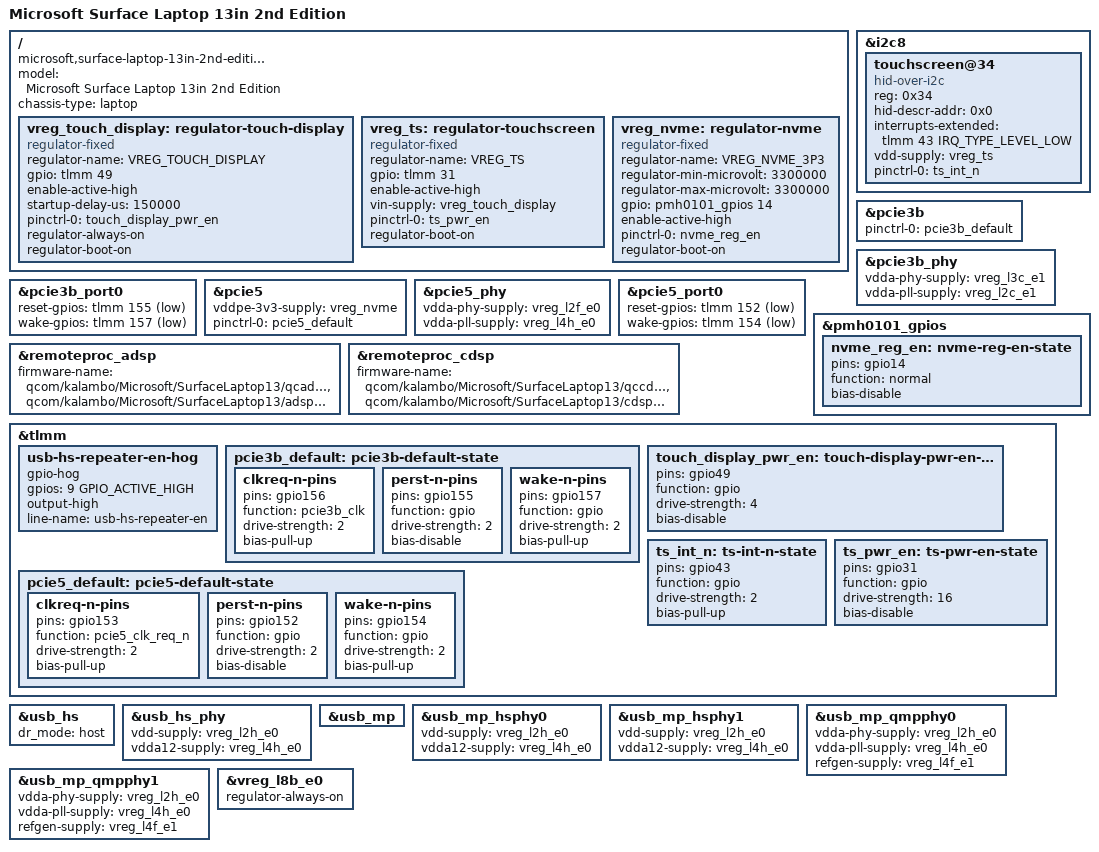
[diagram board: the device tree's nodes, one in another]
// SPDX-License-Identifier: BSD-3-Clause
/*
 * Microsoft Surface Laptop 13-inch (2nd Edition), model 2145, with the
 * 6-core Snapdragon X2 Plus X2P-42-100 (Kalambo).
 *
 * Written from the ACPI tables in Microsoft's firmware download
 * (Surface_UEFI_8.5175.155). Next to the parts kalambo-microsoft-surface.dtsi
 * shares with the Surface Pro 12-inch (2nd Edition), the laptop has a
 * touchscreen (MSHW0816) at 0x34 behind the switch the panel also depends
 * on, as on the Surface Laptop 8 15-inch. It has the USB 2.0 controller
 * (ACPI USB4 @ 0xa200000) with one internal port, and the multiport
 * controller (ACPI USB3) with the USB-A port; the ACPI tables have no I2C
 * keyboard or touchpad. Its drive is NVMe: the INA4230 power monitor
 * channel is STORAGE_SSD_3P3V.
 *
 * Copyright (c) Qualcomm Technologies, Inc. and/or its subsidiaries.
 */
/dts-v1/;

#include "kalambo.dtsi"
#include "kalambo-microsoft-surface.dtsi"

/ {
	model = "Microsoft Surface Laptop 13in 2nd Edition";
	compatible = "microsoft,surface-laptop-13in-2nd-edition", "qcom,kalambo";
	chassis-type = "laptop";

	/*
	 * ACPI power resource TDPR: TLMM 49, then 150 ms. Both the touchscreen
	 * (ITCH) and the panel (GPU0.MON0) depend on it, so it stays on.
	 */
	vreg_touch_display: regulator-touch-display {
		compatible = "regulator-fixed";

		regulator-name = "VREG_TOUCH_DISPLAY";

		gpio = <&tlmm 49 GPIO_ACTIVE_HIGH>;
		enable-active-high;
		startup-delay-us = <150000>;

		pinctrl-0 = <&touch_display_pwr_en>;
		pinctrl-names = "default";

		regulator-always-on;
		regulator-boot-on;
	};

	/* ACPI ITCH _PS0 drives TLMM 31 high and _PS3 drives it low. */
	vreg_ts: regulator-touchscreen {
		compatible = "regulator-fixed";

		regulator-name = "VREG_TS";

		gpio = <&tlmm 31 GPIO_ACTIVE_HIGH>;
		enable-active-high;

		vin-supply = <&vreg_touch_display>;

		pinctrl-0 = <&ts_pwr_en>;
		pinctrl-names = "default";

		regulator-boot-on;
	};

	vreg_nvme: regulator-nvme {
		compatible = "regulator-fixed";

		regulator-name = "VREG_NVME_3P3";
		regulator-min-microvolt = <3300000>;
		regulator-max-microvolt = <3300000>;

		gpio = <&pmh0101_gpios 14 GPIO_ACTIVE_HIGH>;
		enable-active-high;

		pinctrl-0 = <&nvme_reg_en>;
		pinctrl-names = "default";

		regulator-boot-on;
	};
};

&i2c8 {
	/*
	 * ACPI \_SB.I2C9.ITCH, MSHW0816: 0x34 at 400 kHz, HID descriptor
	 * register 0 (its _DSM function 1 returns 0), interrupt TLMM 43 level
	 * low with a pull-up.
	 */
	touchscreen@34 {
		compatible = "hid-over-i2c";
		reg = <0x34>;
		hid-descr-addr = <0x0>;
		interrupts-extended = <&tlmm 43 IRQ_TYPE_LEVEL_LOW>;
		vdd-supply = <&vreg_ts>;

		pinctrl-0 = <&ts_int_n>;
		pinctrl-names = "default";
	};
};

/*
 * ACPI PCI5 and PCI7 both declare an NVMe drive (NVME), and which port the
 * firmware enables (PRP5, PRP7) is filled in at boot. PCI5 is the Surface
 * Laptop 8's drive port; PCI7 (pcie3b, @ 0x74000000) is a port the Surface
 * Laptop 8 uses for an external card slot and this laptop's tables turn
 * into a plain NVMe port. Both are described; the one without a drive
 * fails link training.
 */
&pcie3b {
	pinctrl-0 = <&pcie3b_default>;
	pinctrl-names = "default";

	status = "okay";
};

/* ACPI PCI7 power table: L3C_E1 at 0.936 V and L2C_E1 at 1.2 V */
&pcie3b_phy {
	vdda-phy-supply = <&vreg_l3c_e1>;
	vdda-pll-supply = <&vreg_l2c_e1>;

	status = "okay";
};

/* ACPI PCI7: reset TLMM 155, wake TLMM 157 (virtual pin 0x240) */
&pcie3b_port0 {
	reset-gpios = <&tlmm 155 GPIO_ACTIVE_LOW>;
	wake-gpios = <&tlmm 157 GPIO_ACTIVE_LOW>;
};

&pcie5 {
	vddpe-3v3-supply = <&vreg_nvme>;

	pinctrl-0 = <&pcie5_default>;
	pinctrl-names = "default";

	status = "okay";
};

&pcie5_phy {
	vdda-phy-supply = <&vreg_l2f_e0>;
	vdda-pll-supply = <&vreg_l4h_e0>;

	status = "okay";
};

/* ACPI PCI5: reset TLMM 152, wake TLMM 154 (virtual pin 0x1c0) */
&pcie5_port0 {
	reset-gpios = <&tlmm 152 GPIO_ACTIVE_LOW>;
	wake-gpios = <&tlmm 154 GPIO_ACTIVE_LOW>;
};

&pmh0101_gpios {
	nvme_reg_en: nvme-reg-en-state {
		pins = "gpio14";
		function = "normal";
		bias-disable;
	};
};

&remoteproc_adsp {
	firmware-name = "qcom/kalambo/Microsoft/SurfaceLaptop13/qcadsp8480.mbn",
			"qcom/kalambo/Microsoft/SurfaceLaptop13/adsp_dtbs.elf";

	status = "okay";
};

&remoteproc_cdsp {
	firmware-name = "qcom/kalambo/Microsoft/SurfaceLaptop13/qccdsp8480.mbn",
			"qcom/kalambo/Microsoft/SurfaceLaptop13/cdsp_dtbs.elf";

	status = "okay";
};

&tlmm {
	/*
	 * ACPI USB4 (the USB 2.0 controller) drives TLMM 9 high in _PS0 and
	 * nothing low again: the enable of its eUSB2 repeater, which has no
	 * I2C address in the tables.
	 */
	usb-hs-repeater-en-hog {
		gpio-hog;
		gpios = <9 GPIO_ACTIVE_HIGH>;
		output-high;
		line-name = "usb-hs-repeater-en";
	};

	pcie3b_default: pcie3b-default-state {
		clkreq-n-pins {
			pins = "gpio156";
			function = "pcie3b_clk";
			drive-strength = <2>;
			bias-pull-up;
		};

		perst-n-pins {
			pins = "gpio155";
			function = "gpio";
			drive-strength = <2>;
			bias-disable;
		};

		wake-n-pins {
			pins = "gpio157";
			function = "gpio";
			drive-strength = <2>;
			bias-pull-up;
		};
	};

	pcie5_default: pcie5-default-state {
		clkreq-n-pins {
			pins = "gpio153";
			function = "pcie5_clk_req_n";
			drive-strength = <2>;
			bias-pull-up;
		};

		perst-n-pins {
			pins = "gpio152";
			function = "gpio";
			drive-strength = <2>;
			bias-disable;
		};

		wake-n-pins {
			pins = "gpio154";
			function = "gpio";
			drive-strength = <2>;
			bias-pull-up;
		};
	};

	touch_display_pwr_en: touch-display-pwr-en-state {
		pins = "gpio49";
		function = "gpio";
		drive-strength = <4>;
		bias-disable;
	};

	ts_int_n: ts-int-n-state {
		pins = "gpio43";
		function = "gpio";
		drive-strength = <2>;
		bias-pull-up;
	};

	ts_pwr_en: ts-pwr-en-state {
		pins = "gpio31";
		function = "gpio";
		drive-strength = <16>;
		bias-disable;
	};
};

/*
 * ACPI USB4 @ 0xa200000, the USB 2.0 controller, with one internal port
 * (_UPC not connectable by the user). Its PHY rails are those of its PEP
 * table: L2H_E0 and L4H_E0.
 */
&usb_hs {
	dr_mode = "host";

	status = "okay";
};

&usb_hs_phy {
	vdd-supply = <&vreg_l2h_e0>;
	vdda12-supply = <&vreg_l4h_e0>;

	status = "okay";
};

/*
 * Multiport controller (ACPI USB3): the USB-A port and an internal port.
 * _PS0 drives the enables of the two eUSB2 repeaters, TLMM 8 and 184, high,
 * and the tables give the repeaters no I2C address, so they are left as
 * the firmware set them, as on the Surface Laptop 8.
 */
&usb_mp {
	status = "okay";
};

&usb_mp_hsphy0 {
	vdd-supply = <&vreg_l2h_e0>;
	vdda12-supply = <&vreg_l4h_e0>;

	status = "okay";
};

&usb_mp_hsphy1 {
	vdd-supply = <&vreg_l2h_e0>;
	vdda12-supply = <&vreg_l4h_e0>;

	status = "okay";
};

&usb_mp_qmpphy0 {
	vdda-phy-supply = <&vreg_l2h_e0>;
	vdda-pll-supply = <&vreg_l4h_e0>;
	refgen-supply = <&vreg_l4f_e1>;

	status = "okay";
};

&usb_mp_qmpphy1 {
	vdda-phy-supply = <&vreg_l2h_e0>;
	vdda-pll-supply = <&vreg_l4h_e0>;
	refgen-supply = <&vreg_l4f_e1>;

	status = "okay";
};

/* The USB 2.0 and multiport power tables vote for L8B_E0 at 3.072 V. */
&vreg_l8b_e0 {
	regulator-always-on;
};
